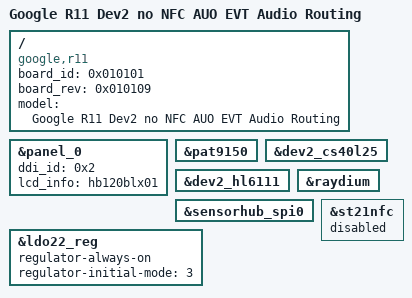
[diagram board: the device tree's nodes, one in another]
/*
 * Google R11 DTSO file
 *
 * Copyright 2020 Google LLC
 *
 * This program is free software; you can redistribute it and/or modify
 * it under the terms of the GNU General Public License version 2 and
 * only version 2 as published by the Free Software Foundation.
 *
 * This program is distributed in the hope that it will be useful,
 * but WITHOUT ANY WARRANTY; without even the implied warranty of
 * MERCHANTABILITY or FITNESS FOR A PARTICULAR PURPOSE.  See the
 * GNU General Public License for more details.
 */

/dts-v1/;
/plugin/;

#include <dt-bindings/clock/exynos9110.h>
#include <dt-bindings/interrupt-controller/arm-gic.h>
#include <dt-bindings/interrupt-controller/exynos9110.h>

#include "r11_dev2_battery.dtsi"
#include "r11_evt1_sound.dtsi"
#include "r11_evt1_speaker.dtsi"

/ {
	compatible = "google,r11";
	board_id = <0x010101>;
	board_rev = <0x010109>;

	fragment@common {
		target-path = "/";
		__overlay__ {
			model = "Google R11 Dev2 no NFC AUO EVT Audio Routing";
		};
	};
};

&panel_0 {
	ddi_id = <0x2>;
	lcd_info = <&hb120blx01>;
};

&pat9150 {
	status = "ok";
};

&dev2_cs40l25 {
	status = "ok";
};

&dev2_hl6111 {
	status = "ok";
};

&raydium {
	status = "ok";
};

&sensorhub_spi0 {
	status = "ok";
};

&st21nfc {
	status = "disabled";
};

&ldo22_reg {
	regulator-always-on;
	regulator-initial-mode = <3>;
};
